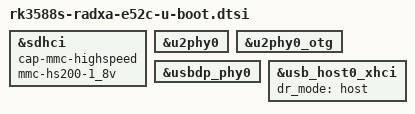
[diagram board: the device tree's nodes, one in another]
// SPDX-License-Identifier: (GPL-2.0+ OR MIT)

#include "rk3588s-u-boot.dtsi"

&sdhci {
	cap-mmc-highspeed;
	mmc-hs200-1_8v;
};

&u2phy0 {
	status = "okay";
};

&u2phy0_otg {
	status = "okay";
};

&usbdp_phy0 {
	status = "okay";
};

&usb_host0_xhci {
	dr_mode = "host";
	status = "okay";
};
